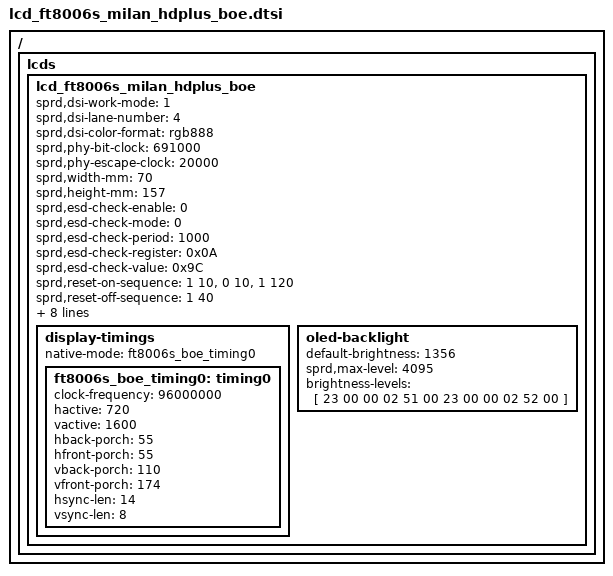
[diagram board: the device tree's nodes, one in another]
/ {
	fragment {
		target-path = "/";
		__overlay__ {
			lcds {
				lcd_ft8006s_milan_hdplus_boe: lcd_ft8006s_milan_hdplus_boe {

					sprd,dsi-work-mode = <1>;
					sprd,dsi-lane-number = <4>;
					sprd,dsi-color-format = "rgb888";

					sprd,phy-bit-clock = <691000>;
					sprd,phy-escape-clock = <20000>;

					sprd,width-mm = <70>;
					sprd,height-mm = <157>;

					sprd,esd-check-enable = <0>;
					sprd,esd-check-mode = <0>;  /*Read register*/
					sprd,esd-check-period = <1000>;
					sprd,esd-check-register = <0x0A>;
					sprd,esd-check-value = <0x9C>;

					sprd,reset-on-sequence = <1 10>, <0 10>, <1 120>;
					sprd,reset-off-sequence = <1 40>;

					sprd,initial-command = [
						 23 00 00 02 41 5A
						 39 00 00 03 41 5A 24
						 23 00 00 02 90 5A
						 39 00 00 03 41 5A 08
						 39 00 00 05 80 C8 2C 11 00
						 39 00 00 03 41 5A 09
						 39 00 00 11 80 00 00 00 00 60 E5 4A 01 40 A0 0C 82 20 08 F0 03
						 39 00 00 11 90 99 24 42 0A E3 91 80 F0 C3 E1 69 D8 66 01 00 00
						 39 00 00 11 A0 01 55 55 00 A0 4D 06 11 0D 60 5A FF FF 03 A5 E6
						 39 00 00 11 B0 08 C9 16 64 0B 00 00 11 01 60 00 FF FF 03 FF 34
						 39 00 00 09 C0 0C 3F 1F 9F 0F 00 08 00
						 39 00 00 03 41 5A 0A
						 39 00 00 11 80 FF 84 8F 03 00 0D 1A 2A 3B 4E 53 86 5E 97 A1 6F
						 39 00 00 11 90 90 68 63 52 40 30 1D 0B 00 0D 1A 2A 3B 4E 53 86
						 39 00 00 0E A0 5E 97 A1 6F 90 68 63 52 40 30 1D 0B 00
						 39 00 00 03 41 5A 0B
						 39 00 00 11 80 00 00 00 00 00 00 60 47 00 00 00 00 00 00 B0 23
						 39 00 00 03 90 15 00
						 39 00 00 03 41 5A 0C
						 39 00 00 11 80 BA 68 68 01 B2 75 B0 04 00 60 15 00 50 15 56 51
						 39 00 00 11 90 15 55 61 15 00 60 15 00 50 15 56 51 15 55 61 95
						 39 00 00 11 A0 AB 18 00 05 00 05 00 05 00 49 29 84 52 01 09 00
						 39 00 00 03 B0 00 00
						 39 00 00 03 41 5A 0D
						 39 00 00 10 80 F0 B1 71 EF 4B C0 80 5A 00 0E 00 C0 12 00 AF
						 39 00 00 03 41 5A 0E
						 39 00 00 0A 80 FF 00 55 55 32 98 76 07 1C
						 39 00 00 03 41 5A 0F
						 39 00 00 11 80 D1 07 70 C0 12 20 64 08 52 51 58 49 03 52 4C 4C
						 39 00 00 11 90 68 68 68 4C 4C 7C 14 00 20 06 C2 00 04 06 0C 40
						 39 00 00 05 A0 00 92 00 04
						 39 00 00 03 41 5A 10
						 39 00 00 11 80 00 00 03 E7 1F 17 10 48 80 AA D0 18 30 88 41 8A
						 39 00 00 10 90 39 28 A9 C5 9A 7B F0 07 7E E0 07 7E 20 10 00
						 39 00 00 03 41 5A 11
						 39 00 00 11 80 49 77 03 00 CA F1 FF 43 30 08 C4 06 A1 D8 24 18
						 39 00 00 11 90 30 C6 66 C1 80 21 15 CB E5 D2 68 6C 36 1D 04 08
						 39 00 00 11  A0 5A D8 88 60 B0 81 40 1A 1B 48 63 03 B9 00 1C 80
						 39 00 00 11  B0 50 30 00 E0 E1 01 00 28 0E 06 43 55 55 55 55 55
						 39 00 00 11 C0 95 88 88 88 88 88 88 08 84 C6 E3 81 00 20 00 21
						 39 00 00 11 D0 42 88 20 00 00 00 40 80 24 32 04 41 26 49 92 04
						 39 00 00 11 E0 00 92 04 00 92 04 00 00 00 00 92 04 00 85 11 0C
						 39 00 00 10 F0 00 00 40 00 00 00 00 5E 4A 55 79 00 08 31 08
						 39 00 00 03 41 5A 12
						 39 00 00 11 80 00 00 00 00 00 02 03 00 00 00 00 02 03 00 41 37
						 39 00 00 11 90 F1 E7 00 00 00 00 00 00 00 00 00 00 00 2D 23 05
						 39 00 00 08 A0 FB 08 2D 23 05 FB 0C
						 39 00 00 03 41 5A 13
						 39 00 00 11 80 FD 0F 00 0C 00 00 00 A0 01 08 01 1C 44 0C CE E7
						 39 00 00 11 90 62 0E 24 98 AC 21 01 00 D0 93 24 49 06 18 88 13
						 39 00 00 11 A0 88 13 88 13 9F B8 8B 58 02 88 13 88 13 58 02 00
						 39 00 00 0C B0 00 00 00 00 00 00 00 00 00 1B 10
						 39 00 00 03 41 5A 14
						 39 00 00 11 80 01 02 41 36 E9 EF F7 FB FD 7E 00 00 00 90 C5 89
						 39 00 00 11 90 27 3D 20 46 3C E9 01 F1 E1 49 0F 88 0D 4F 7A 00
						 39 00 00 11 A0 00 00 00 00 00 00 00 00 00 00 00 00 00 00 00 00
						 39 00 00 11 B0 00 00 00 00 00 00 00 00 00 1C B2 21 2B 00 40 A1
						 39 00 00 11 C0 50 78 07 5A F2 90 51 1C 6F 40 4B 1E 32 8A E3 05
						 39 00 00 11 D0 68 C9 43 46 71 BC 02 2D 79 C8 28 8E 77 A1 25 0F
						 39 00 00 11 E0 19 C5 F1 26 B4 E4 21 A3 38 DE 83 96 3C 64 14 C7
						 39 00 00 11 F0 5B D0 92 87 8C E2 18 01 BF 5F 08 00 00 00 00 00
						 39 00 00 03 41 5A 15
						 39 00 00 11 80 00 00 00 00 00 00 00 00 00 00 00 00 52 D9 E0 F7
						 39 00 00 11 90 A3 00 20 4B 85 AA D5 06 91 91 57 A1 6A B5 41 64
						 39 00 00 11 A0 78 00 00 00 00 00 00 00 00 00 00 00 00 00 00 00
						 39 00 00 11 B0 04 00 00 00 00 00 00 40 12 00 00 00 94 96 0C 4D
						 39 00 00 11 C0 C9 02 41 C1 50 9C B6 6D DB B6 6D DB B6 6D C1 D0
						 39 00 00 11 D0 A4 20 12 64 10 02 68 DB B6 6D DB B6 6D DB 96 0C
						 39 00 00 11 E0 4D 88 02 41 80 40 98 B6 6D DB B6 6D DB B6 6D C1
						 39 00 00 11 F0 D0 B4 24 12 74 14 43 68 DB B6 6D DB B6 6D 5B C0
						 39 00 00 03 41 5A 16
						 39 00 00 11 80 C3 43 41 01 00 00 00 00 00 00 00 00 00 00 00 00
						 39 00 00 07 90 00 00 00 00 F0 20
						 39 00 00 03 41 5A 18
						 39 00 00 11 80 04 FF 00 80 80 00 04 20 00 01 08 40 00 02 10 80
						 39 00 00 03 90 00 04
						 39 00 00 03 41 5A 19
						 39 00 00 11 80 C0 AF A3 9B 92 8D 8A 86 84 83 82 81 00 50 F6 CF
						 39 00 00 11 90 FC 2F F3 EF CF BF 0F FF AF B5 71 0E 6C 4A 69 08
						 39 00 00 05 A0 05 05 02 00
						 39 00 00 03 41 5A 1A
						 39 00 00 11 80 00 04 08 0C 00 10 14 18 1C 00 20 28 30 38 00 40
						 39 00 00 11 90 48 50 58 00 60 68 70 78 00 80 88 90 98 00 A0 A8
						 39 00 00 11 A0 B0 B8 00 C0 C8 D0 D8 00 E0 E8 F0 F8 00 FC FE FF
						 39 00 00 11 B0 00 00 04 08 0C 00 10 14 18 1C 00 20 28 30 38 00
						 39 00 00 11 C0 40 48 50 58 00 60 68 70 78 00 80 88 90 98 00 A0
						 39 00 00 11 D0 A8 B0 B8 00 C0 C8 D0 D8 00 E0 E8 F0 F8 00 FC FE
						 39 00 00 11 E0 FF 00 00 04 08 0C 00 10 14 18 1C 00 20 28 30 38
						 39 00 00 11 F0 00 40 48 50 58 00 60 68 70 78 00 80 88 90 98 00
						 39 00 00 03 41 5A 1B
						 39 00 00 11 80 A0 A8 B0 B8 00 C0 C8 D0 D8 00 E0 E8 F0 F8 00 FC
						 39 00 00 05 90 FE FF 00 00
						 39 00 00 03 41 5A 20
						 39 00 00 08 80 84 00 02 14 00 00 00
						 39 00 00 03 41 5A 22
						 39 00 00 0E 80 2D D3 00 55 55 55 55 55 55 55 55 9F 00
						 39 00 00 03 41 5A 23
						 39 00 00 11 80 00 00 00 05 00 00 00 00 00 00 00 00 00 00 00 00
						 39 00 00 0D 90 FF 0F 00 00 00 03 00 00 00 FF 07 35
						 39 00 00 03 41 5A 24
						 39 00 00 11 80 00 03 00 FF FF 20 00 00 00 00 00 00 00 00 03 CA
						 39 00 00 11 90 5A 5A 5A 55 00 00 00 00 00 00 00 00 00 00 00 00
						 23 00 00 02 42 24
						 23 00 00 02 90 00
						 39 00 00 03 41 5A 2F
						 23 00 00 02 19 01
						 23 00 00 02 4C 03						 
						 23 00 00 02 53 2C
						 23 00 00 02 55 00
						 23 78 00 02 11 00
						 23 23 00 02 29 00
						];
			sprd,page-unlock-command = [
			39 00 00 03 F0 5A 59  
			39 00 00 03 F1 A5 A6
						];
					sprd,sleep-in-command = [
			23 14 00 02 28 00
			23 78 00 02 10 00
						];
					sprd,sleep-out-command = [
			23 78 00 23 11 00
			23 14 00 23 29 00
						];

					display-timings {
						native-mode = <&ft8006s_boe_timing0>;

						ft8006s_boe_timing0: timing0 {
							clock-frequency = <96000000>;
				hactive = <720>;
				vactive = <1600>;
				hback-porch = <55>;
				hfront-porch = <55>;
				vback-porch = <110>;
				vfront-porch = <174>;
				hsync-len = <14>;
				vsync-len = <8>;
						};
					};
					
				oled-backlight {			
						default-brightness = <1356>;	
						sprd,max-level = <4095>;
						brightness-levels = [				
            		    	23 00 00 02 51 00
							23 00 00 02 52 00
						];
					};					
				};
			};
		};
	};
};

